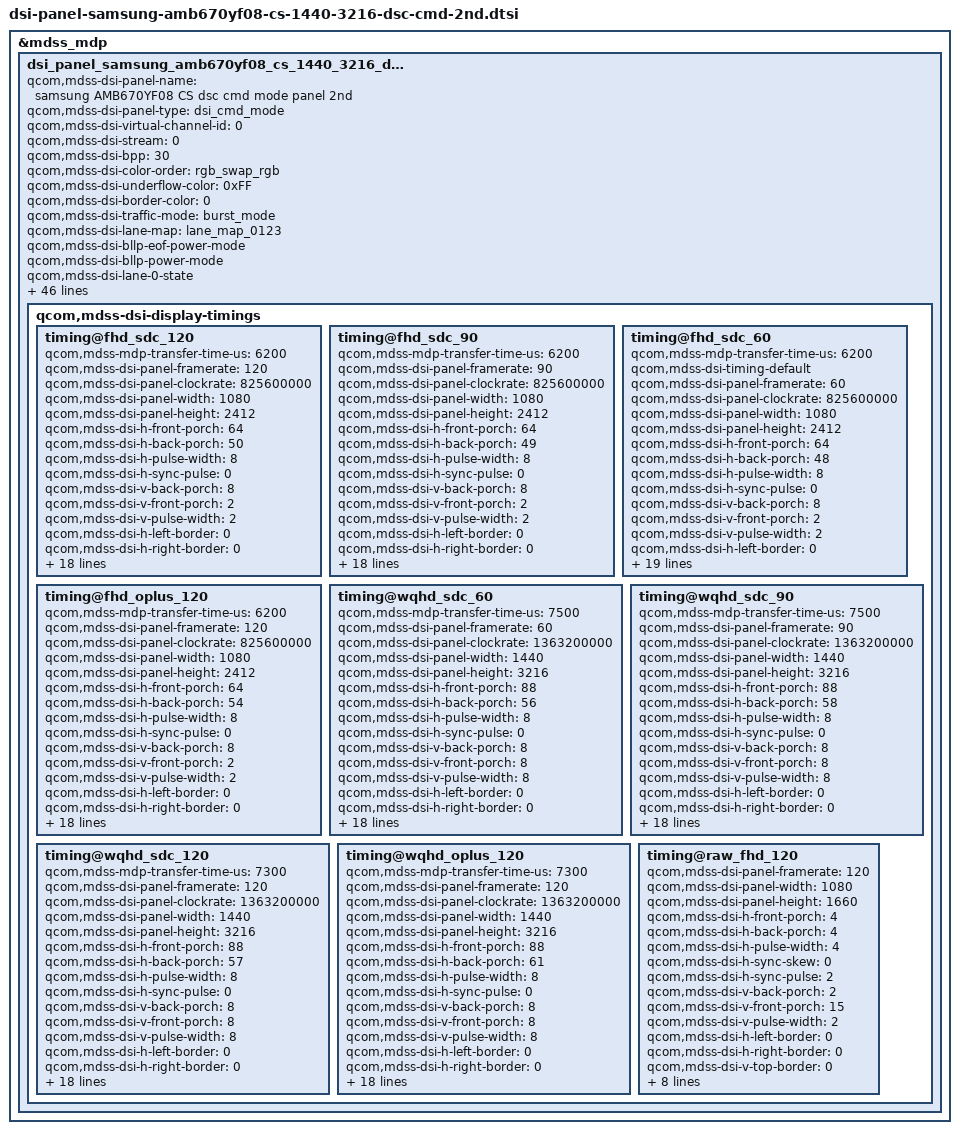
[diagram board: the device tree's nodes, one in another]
&mdss_mdp {
	dsi_panel_samsung_amb670yf08_cs_1440_3216_dsc_cmd_2nd: qcom,mdss_dsi_panel_samsung_amb670yf08_cs_1440_3216_dsc_cmd_2nd {
		qcom,mdss-dsi-panel-name = "samsung AMB670YF08 CS dsc cmd mode panel 2nd";
		qcom,mdss-dsi-panel-type = "dsi_cmd_mode";
		qcom,mdss-dsi-virtual-channel-id = <0>;
		qcom,mdss-dsi-stream = <0>;
		qcom,mdss-dsi-bpp = <30>;
		qcom,mdss-dsi-color-order = "rgb_swap_rgb";
		qcom,mdss-dsi-underflow-color = <0xFF>;
		qcom,mdss-dsi-border-color = <0>;
		//qcom,dsi-ctrl-num = <0>;
		//qcom,dsi-phy-num = <0>;
		qcom,mdss-dsi-traffic-mode = "burst_mode";
		qcom,mdss-dsi-lane-map = "lane_map_0123";
		qcom,mdss-dsi-bllp-eof-power-mode;
		qcom,mdss-dsi-bllp-power-mode;
		qcom,mdss-dsi-lane-0-state;
		qcom,mdss-dsi-lane-1-state;
		qcom,mdss-dsi-lane-2-state;
		qcom,mdss-dsi-lane-3-state;
		qcom,mdss-dsi-dma-trigger = "trigger_sw";
		qcom,mdss-dsi-mdp-trigger = "none";
		qcom,mdss-dsi-reset-sequence = <1 10>, <0 5>, <1 10>;
		qcom,mdss-pan-physical-width-dimension = <70>;
		qcom,mdss-pan-physical-height-dimension = <156>;
		qcom,mdss-dsi-te-check-enable;
		qcom,mdss-dsi-te-using-te-pin;
		qcom,mdss-dsi-te-pin-select = <1>;
		qcom,mdss-dsi-te-dcs-command = <1>;
		qcom,mdss-dsi-wr-mem-start = <0x2C>;
		qcom,mdss-dsi-wr-mem-continue = <0x3C>;
		qcom,mdss-dsi-lp11-init;
		qcom,mdss-dsi-init-delay-us = <1000>;
		qcom,mdss-dsi-panel-jitter = <0x4 0x1>;
		qcom,dynamic-mode-switch-enabled;
		qcom,dynamic-mode-switch-type = "dynamic-resolution-switch-immediate";
		/* HDR Setting */
		qcom,mdss-dsi-panel-hdr-enabled;
		qcom,mdss-dsi-panel-hdr-color-primaries = <15635 16450 34000 16000 13250 34500 7500 3000>;
		qcom,mdss-dsi-panel-peak-brightness = <5400000>;
		qcom,mdss-dsi-panel-average-brightness = <2000000>;
		qcom,mdss-dsi-panel-blackness-level = <2000>;

		//qcom,esd-check-enabled;
		qcom,mdss-dsi-panel-status-check-mode = "reg_read";
		qcom,mdss-dsi-panel-status-command = [06 00 00 00 00 00 01 0A];
		qcom,mdss-dsi-panel-status-command-state = "dsi_lp_mode";
		qcom,mdss-dsi-panel-status-value = <
			0x9F
			0x9D
		>;
		qcom,mdss-dsi-panel-status-read-length = <1>;
		oplus,mdss-dsi-panel-status-match-modes = <0x00000000>;

		qcom,mdss-dsi-display-timings {
			timing@fhd_sdc_120 {
				//#include "../dsi-panel-samsung-amb670yf07-1440-3216-dsc-cmd-120fps-common.dtsi"
				qcom,mdss-mdp-transfer-time-us = <6200>;
				qcom,mdss-dsi-panel-framerate = <120>;
				qcom,mdss-dsi-panel-clockrate = <825600000>;
				qcom,mdss-dsi-panel-width = <1080>;
				qcom,mdss-dsi-panel-height = <2412>;
				qcom,mdss-dsi-h-front-porch = <64>;
				qcom,mdss-dsi-h-back-porch = <50>;
				qcom,mdss-dsi-h-pulse-width = <8>;
				qcom,mdss-dsi-h-sync-pulse = <0>;
				qcom,mdss-dsi-v-back-porch = <8>;
				qcom,mdss-dsi-v-front-porch = <2>;
				qcom,mdss-dsi-v-pulse-width = <2>;
				qcom,mdss-dsi-h-left-border = <0>;
				qcom,mdss-dsi-h-right-border = <0>;
				qcom,mdss-dsi-v-top-border = <0>;
				qcom,mdss-dsi-v-bottom-border = <0>;
				qcom,mdss-dsi-panel-jitter = <0x4 0x1>;

				qcom,lm-split = <540 540>;
				qcom,mdss-dsc-slice-height = <36>;
				qcom,mdss-dsc-slice-width = <540>;
				qcom,compression-mode = "dsc";
				qcom,mdss-dsc-encoders = <2>;
				qcom,mdss-dsc-slice-per-pkt = <2>;
				qcom,mdss-dsc-bit-per-component = <10>;
				qcom,mdss-dsc-bit-per-pixel = <8>;
				qcom,mdss-dsc-version = <0x11>;
				qcom,mdss-dsc-scr-version = <1>;
				qcom,mdss-dsc-block-prediction-enable;
			};

			timing@fhd_sdc_90 {
				//#include "../dsi-panel-samsung-amb670yf07-1440-3216-dsc-cmd-90fps-common.dtsi"
				qcom,mdss-mdp-transfer-time-us = <6200>;
				qcom,mdss-dsi-panel-framerate = <90>;
				qcom,mdss-dsi-panel-clockrate = <825600000>;
				qcom,mdss-dsi-panel-width = <1080>;
				qcom,mdss-dsi-panel-height = <2412>;
				qcom,mdss-dsi-h-front-porch = <64>;
				qcom,mdss-dsi-h-back-porch = <49>;
				qcom,mdss-dsi-h-pulse-width = <8>;
				qcom,mdss-dsi-h-sync-pulse = <0>;
				qcom,mdss-dsi-v-back-porch = <8>;
				qcom,mdss-dsi-v-front-porch = <2>;
				qcom,mdss-dsi-v-pulse-width = <2>;
				qcom,mdss-dsi-h-left-border = <0>;
				qcom,mdss-dsi-h-right-border = <0>;
				qcom,mdss-dsi-v-top-border = <0>;
				qcom,mdss-dsi-v-bottom-border = <0>;
				qcom,mdss-dsi-panel-jitter = <0x4 0x1>;

				qcom,lm-split = <540 540>;
				qcom,mdss-dsc-slice-height = <36>;
				qcom,mdss-dsc-slice-width = <540>;
				qcom,compression-mode = "dsc";
				qcom,mdss-dsc-encoders = <2>;
				qcom,mdss-dsc-slice-per-pkt = <2>;
				qcom,mdss-dsc-bit-per-component = <10>;
				qcom,mdss-dsc-bit-per-pixel = <8>;
				qcom,mdss-dsc-version = <0x11>;
				qcom,mdss-dsc-scr-version = <1>;
				qcom,mdss-dsc-block-prediction-enable;
			};

			timing@fhd_sdc_60 {
				//#include "../dsi-panel-samsung-amb670yf07-1440-3216-dsc-cmd-60fps-common.dtsi"
				qcom,mdss-mdp-transfer-time-us = <6200>;
				qcom,mdss-dsi-timing-default;
				qcom,mdss-dsi-panel-framerate = <60>;
				qcom,mdss-dsi-panel-clockrate = <825600000>;
				qcom,mdss-dsi-panel-width = <1080>;
				qcom,mdss-dsi-panel-height = <2412>;
				qcom,mdss-dsi-h-front-porch = <64>;
				qcom,mdss-dsi-h-back-porch = <48>;
				qcom,mdss-dsi-h-pulse-width = <8>;
				qcom,mdss-dsi-h-sync-pulse = <0>;
				qcom,mdss-dsi-v-back-porch = <8>;
				qcom,mdss-dsi-v-front-porch = <2>;
				qcom,mdss-dsi-v-pulse-width = <2>;
				qcom,mdss-dsi-h-left-border = <0>;
				qcom,mdss-dsi-h-right-border = <0>;
				qcom,mdss-dsi-v-top-border = <0>;
				qcom,mdss-dsi-v-bottom-border = <0>;
				qcom,mdss-dsi-panel-jitter = <0x4 0x1>;

				qcom,lm-split = <540 540>;
				qcom,mdss-dsc-slice-height = <36>;
				qcom,mdss-dsc-slice-width = <540>;
				qcom,compression-mode = "dsc";
				qcom,mdss-dsc-encoders = <2>;
				qcom,mdss-dsc-slice-per-pkt = <2>;
				qcom,mdss-dsc-bit-per-component = <10>;
				qcom,mdss-dsc-bit-per-pixel = <8>;
				qcom,mdss-dsc-version = <0x11>;
				qcom,mdss-dsc-scr-version = <1>;
				qcom,mdss-dsc-block-prediction-enable;
			};

			timing@fhd_oplus_120 {
				//#include "../dsi-panel-samsung-amb670yf07-1440-3216-dsc-cmd-120fps-common.dtsi"
				qcom,mdss-mdp-transfer-time-us = <6200>;
				qcom,mdss-dsi-panel-framerate = <120>;
				qcom,mdss-dsi-panel-clockrate = <825600000>;
				qcom,mdss-dsi-panel-width = <1080>;
				qcom,mdss-dsi-panel-height = <2412>;
				qcom,mdss-dsi-h-front-porch = <64>;
				qcom,mdss-dsi-h-back-porch = <54>;
				qcom,mdss-dsi-h-pulse-width = <8>;
				qcom,mdss-dsi-h-sync-pulse = <0>;
				qcom,mdss-dsi-v-back-porch = <8>;
				qcom,mdss-dsi-v-front-porch = <2>;
				qcom,mdss-dsi-v-pulse-width = <2>;
				qcom,mdss-dsi-h-left-border = <0>;
				qcom,mdss-dsi-h-right-border = <0>;
				qcom,mdss-dsi-v-top-border = <0>;
				qcom,mdss-dsi-v-bottom-border = <0>;
				qcom,mdss-dsi-panel-jitter = <0x4 0x1>;

				qcom,lm-split = <540 540>;
				qcom,mdss-dsc-slice-height = <36>;
				qcom,mdss-dsc-slice-width = <540>;
				qcom,compression-mode = "dsc";
				qcom,mdss-dsc-encoders = <2>;
				qcom,mdss-dsc-slice-per-pkt = <2>;
				qcom,mdss-dsc-bit-per-component = <10>;
				qcom,mdss-dsc-bit-per-pixel = <8>;
				qcom,mdss-dsc-version = <0x11>;
				qcom,mdss-dsc-scr-version = <1>;
				qcom,mdss-dsc-block-prediction-enable;
			};

			timing@wqhd_sdc_60 {
				//#include "../dsi-panel-samsung-amb670yf07-1440-3216-dsc-cmd-60fps-common.dtsi"
				qcom,mdss-mdp-transfer-time-us = <7500>;
				qcom,mdss-dsi-panel-framerate = <60>;
				qcom,mdss-dsi-panel-clockrate = <1363200000>;
				qcom,mdss-dsi-panel-width = <1440>;
				qcom,mdss-dsi-panel-height = <3216>;
				qcom,mdss-dsi-h-front-porch = <88>;
				qcom,mdss-dsi-h-back-porch = <56>;
				qcom,mdss-dsi-h-pulse-width = <8>;
				qcom,mdss-dsi-h-sync-pulse = <0>;
				qcom,mdss-dsi-v-back-porch = <8>;
				qcom,mdss-dsi-v-front-porch = <8>;
				qcom,mdss-dsi-v-pulse-width = <8>;
				qcom,mdss-dsi-h-left-border = <0>;
				qcom,mdss-dsi-h-right-border = <0>;
				qcom,mdss-dsi-v-top-border = <0>;
				qcom,mdss-dsi-v-bottom-border = <0>;
				qcom,mdss-dsi-panel-jitter = <0x4 0x1>;

				qcom,lm-split = <720 720>;
				qcom,mdss-dsc-slice-height = <24>;
				qcom,mdss-dsc-slice-width = <720>;
				qcom,compression-mode = "dsc";
				qcom,mdss-dsc-encoders = <2>;
				qcom,mdss-dsc-slice-per-pkt = <2>;
				qcom,mdss-dsc-bit-per-component = <10>;
				qcom,mdss-dsc-bit-per-pixel = <8>;
				qcom,mdss-dsc-version = <0x11>;
				qcom,mdss-dsc-scr-version = <1>;
				qcom,mdss-dsc-block-prediction-enable;
			};

			timing@wqhd_sdc_90 {
				//#include "../dsi-panel-samsung-amb670yf07-1440-3216-dsc-cmd-90fps-common.dtsi"
				qcom,mdss-mdp-transfer-time-us = <7500>;
				qcom,mdss-dsi-panel-framerate = <90>;
				qcom,mdss-dsi-panel-clockrate = <1363200000>;
				qcom,mdss-dsi-panel-width = <1440>;
				qcom,mdss-dsi-panel-height = <3216>;
				qcom,mdss-dsi-h-front-porch = <88>;
				qcom,mdss-dsi-h-back-porch = <58>;
				qcom,mdss-dsi-h-pulse-width = <8>;
				qcom,mdss-dsi-h-sync-pulse = <0>;
				qcom,mdss-dsi-v-back-porch = <8>;
				qcom,mdss-dsi-v-front-porch = <8>;
				qcom,mdss-dsi-v-pulse-width = <8>;
				qcom,mdss-dsi-h-left-border = <0>;
				qcom,mdss-dsi-h-right-border = <0>;
				qcom,mdss-dsi-v-top-border = <0>;
				qcom,mdss-dsi-v-bottom-border = <0>;
				qcom,mdss-dsi-panel-jitter = <0x4 0x1>;

				qcom,lm-split = <720 720>;
				qcom,mdss-dsc-slice-height = <24>;
				qcom,mdss-dsc-slice-width = <720>;
				qcom,compression-mode = "dsc";
				qcom,mdss-dsc-encoders = <2>;
				qcom,mdss-dsc-slice-per-pkt = <2>;
				qcom,mdss-dsc-bit-per-component = <10>;
				qcom,mdss-dsc-bit-per-pixel = <8>;
				qcom,mdss-dsc-version = <0x11>;
				qcom,mdss-dsc-scr-version = <1>;
				qcom,mdss-dsc-block-prediction-enable;
			};

			timing@wqhd_sdc_120 {
				//#include "../dsi-panel-samsung-amb670yf07-1440-3216-dsc-cmd-120fps-common.dtsi"
				qcom,mdss-mdp-transfer-time-us = <7300>;
				qcom,mdss-dsi-panel-framerate = <120>;
				qcom,mdss-dsi-panel-clockrate = <1363200000>;
				qcom,mdss-dsi-panel-width = <1440>;
				qcom,mdss-dsi-panel-height = <3216>;
				qcom,mdss-dsi-h-front-porch = <88>;
				qcom,mdss-dsi-h-back-porch = <57>;
				qcom,mdss-dsi-h-pulse-width = <8>;
				qcom,mdss-dsi-h-sync-pulse = <0>;
				qcom,mdss-dsi-v-back-porch = <8>;
				qcom,mdss-dsi-v-front-porch = <8>;
				qcom,mdss-dsi-v-pulse-width = <8>;
				qcom,mdss-dsi-h-left-border = <0>;
				qcom,mdss-dsi-h-right-border = <0>;
				qcom,mdss-dsi-v-top-border = <0>;
				qcom,mdss-dsi-v-bottom-border = <0>;
				qcom,mdss-dsi-panel-jitter = <0x4 0x1>;

				qcom,lm-split = <720 720>;
				qcom,mdss-dsc-slice-height = <24>;
				qcom,mdss-dsc-slice-width = <720>;
				qcom,compression-mode = "dsc";
				qcom,mdss-dsc-encoders = <2>;
				qcom,mdss-dsc-slice-per-pkt = <2>;
				qcom,mdss-dsc-bit-per-component = <10>;
				qcom,mdss-dsc-bit-per-pixel = <8>;
				qcom,mdss-dsc-version = <0x11>;
				qcom,mdss-dsc-scr-version = <1>;
				qcom,mdss-dsc-block-prediction-enable;
			};

			timing@wqhd_oplus_120 {
				//#include "../dsi-panel-samsung-amb670yf07-1440-3216-dsc-cmd-120fps-common.dtsi"
				qcom,mdss-mdp-transfer-time-us = <7300>;
				qcom,mdss-dsi-panel-framerate = <120>;
				qcom,mdss-dsi-panel-clockrate = <1363200000>;
				qcom,mdss-dsi-panel-width = <1440>;
				qcom,mdss-dsi-panel-height = <3216>;
				qcom,mdss-dsi-h-front-porch = <88>;
				qcom,mdss-dsi-h-back-porch = <61>;
				qcom,mdss-dsi-h-pulse-width = <8>;
				qcom,mdss-dsi-h-sync-pulse = <0>;
				qcom,mdss-dsi-v-back-porch = <8>;
				qcom,mdss-dsi-v-front-porch = <8>;
				qcom,mdss-dsi-v-pulse-width = <8>;
				qcom,mdss-dsi-h-left-border = <0>;
				qcom,mdss-dsi-h-right-border = <0>;
				qcom,mdss-dsi-v-top-border = <0>;
				qcom,mdss-dsi-v-bottom-border = <0>;
				qcom,mdss-dsi-panel-jitter = <0x4 0x1>;

				qcom,lm-split = <720 720>;
				qcom,mdss-dsc-slice-height = <24>;
				qcom,mdss-dsc-slice-width = <720>;
				qcom,compression-mode = "dsc";
				qcom,mdss-dsc-encoders = <2>;
				qcom,mdss-dsc-slice-per-pkt = <2>;
				qcom,mdss-dsc-bit-per-component = <10>;
				qcom,mdss-dsc-bit-per-pixel = <8>;
				qcom,mdss-dsc-version = <0x11>;
				qcom,mdss-dsc-scr-version = <1>;
				qcom,mdss-dsc-block-prediction-enable;
			};
			timing@raw_fhd_120 {
				qcom,mdss-dsi-panel-framerate = <120>;
				//qcom,mdss-dsi-panel-clockrate = <1320000000>;
				qcom,mdss-dsi-panel-width = <1080>;
				qcom,mdss-dsi-panel-height = <1660>;
				qcom,mdss-dsi-h-front-porch = <4>;
				qcom,mdss-dsi-h-back-porch = <4>;
				qcom,mdss-dsi-h-pulse-width = <4>;
				qcom,mdss-dsi-h-sync-skew = <0>;
				qcom,mdss-dsi-h-sync-pulse = <2>;
				qcom,mdss-dsi-v-back-porch = <2>;
				qcom,mdss-dsi-v-front-porch = <15>;
				qcom,mdss-dsi-v-pulse-width = <2>;
				qcom,mdss-dsi-h-left-border = <0>;
				qcom,mdss-dsi-h-right-border = <0>;
				qcom,mdss-dsi-v-top-border = <0>;
				qcom,mdss-dsi-v-bottom-border = <0>;
				qcom,mdss-dsi-panel-jitter = <0x4 0x1>;
			};
		};
	};
};

&dsi_panel_samsung_amb670yf08_cs_1440_3216_dsc_cmd_2nd {
	/* brightness config */
	qcom,mdss-dsi-bl-min-level = <1>;
	qcom,mdss-dsi-bl-max-level = <4095>;
	qcom,mdss-dsi-bl-inverted-dbv;
	qcom,mdss-dsi-bl-normal-max-level = <2047>;
	qcom,bl-dsc-cmd-state = "dsi_lp_mode";
	qcom,mdss-brightness-default-level = <1433>;
	qcom,mdss-brightness-max-level = <4095>;
	qcom,mdss-brightness-normal-max-level = <2047>;
	qcom,mdss-dsi-dc-backlight-level = <520>;

	qcom,mdss-dsi-display-timings {
		timing@fhd_sdc_120 {
			qcom,mdss-dsi-panel-phy-timings = [00 1C 07 07 17 22 07 07 08 02 04 00 18 0C];
			qcom,display-topology = <1 1 1>,<2 2 1>;
			qcom,default-topology-index = <1>;
		};
		timing@fhd_sdc_90 {
			qcom,mdss-dsi-panel-phy-timings = [00 1C 07 07 17 22 07 07 08 02 04 00 18 0C];
			qcom,display-topology = <1 1 1>,<2 2 1>;
			qcom,default-topology-index = <1>;
		};
		timing@fhd_sdc_60 {
			qcom,mdss-dsi-panel-phy-timings = [00 1C 07 07 17 22 07 07 08 02 04 00 18 0C];
			qcom,display-topology = <1 1 1>,<2 2 1>;
			qcom,default-topology-index = <1>;
		};
		timing@fhd_oplus_120 {
			qcom,mdss-dsi-panel-phy-timings = [00 1C 07 07 17 22 07 07 08 02 04 00 18 0C];
			qcom,display-topology = <1 1 1>,<2 2 1>;
			qcom,default-topology-index = <1>;
		};
		timing@wqhd_sdc_60 {
			qcom,mdss-dsi-panel-phy-timings = [00 2C 0C 0C 1D 26 0C 0C 0B 02 04 00 24 11];
			qcom,display-topology = <1 1 1>,<2 2 1>;
			qcom,default-topology-index = <1>;
		};
		timing@wqhd_sdc_90 {
			qcom,mdss-dsi-panel-phy-timings = [00 2C 0C 0C 1D 26 0C 0C 0B 02 04 00 24 11];
			qcom,display-topology = <1 1 1>,<2 2 1>;
			qcom,default-topology-index = <1>;
		};
		timing@wqhd_sdc_120 {
			qcom,mdss-dsi-panel-phy-timings = [00 2C 0C 0C 1D 26 0C 0C 0B 02 04 00 24 11];
			qcom,display-topology = <1 1 1>,<2 2 1>;
			qcom,default-topology-index = <1>;
		};
		timing@wqhd_oplus_120 {
			qcom,mdss-dsi-panel-phy-timings = [00 2C 0C 0C 1D 26 0C 0C 0B 02 04 00 24 11];
			qcom,display-topology = <1 1 1>,<2 2 1>;
			qcom,default-topology-index = <1>;
		};
		timing@raw_fhd_120 {
			qcom,mdss-dsi-panel-clockrate = <1440000000>;
			qcom,mdss-mdp-transfer-time-us = <7468>;  //same as main panel
			qcom,mdss-dsi-panel-phy-timings = [00 2E 0C 0C 1D 1B 0C 0D 0B 02 04 00 25 11];
			qcom,display-topology = <1 0 1>,<2 0 1>;
			qcom,default-topology-index = <0>;
		};
	};
};

